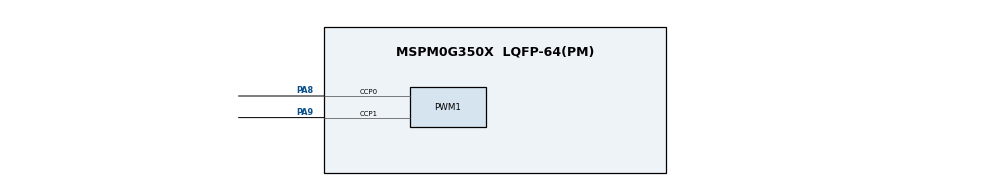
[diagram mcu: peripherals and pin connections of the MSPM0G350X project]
/**
 * @cliArgs --device "MSPM0G350X" --part "Default" --package "LQFP-64(PM)" --product "mspm0_sdk@2.05.01.01"
 * @versions {"tool":"1.24.0+4110"}
 */

/**
 * Import the modules used in this configuration.
 */
const ADC12         = scripting.addModule("/ti/driverlib/ADC12", {}, false);
const ADC121        = ADC12.addInstance();
const Board         = scripting.addModule("/ti/driverlib/Board");
const MATHACL       = scripting.addModule("/ti/driverlib/MATHACL");
const PWM           = scripting.addModule("/ti/driverlib/PWM", {}, false);
const PWM1          = PWM.addInstance();
const SYSCTL        = scripting.addModule("/ti/driverlib/SYSCTL");
const ProjectConfig = scripting.addModule("/ti/project_config/ProjectConfig");

/**
 * Write custom configuration values to the imported modules.
 */
const divider9       = system.clockTree["UDIV"];
divider9.divideValue = 2;

const multiplier2         = system.clockTree["PLL_QDIV"];
multiplier2.multiplyValue = 6;

const mux4       = system.clockTree["EXHFMUX"];
mux4.inputSelect = "EXHFMUX_XTAL";

const mux8       = system.clockTree["HSCLKMUX"];
mux8.inputSelect = "HSCLKMUX_SYSPLL0";

const mux12       = system.clockTree["SYSPLLMUX"];
mux12.inputSelect = "zSYSPLLMUX_HFCLK";

const pinFunction4        = system.clockTree["HFXT"];
pinFunction4.enable       = true;
pinFunction4.HFXTStartup  = 16;
pinFunction4.inputFreq    = 20;
pinFunction4.HFCLKMonitor = true;

ADC121.$name              = "ADC12_0";
ADC121.adcMem0chansel     = "DL_ADC12_INPUT_CHAN_11";
ADC121.repeatMode         = true;
ADC121.sampleTime0        = "50 us";
ADC121.enabledInterrupts  = ["DL_ADC12_INTERRUPT_MEM0_RESULT_LOADED"];
ADC121.adcMem0trig        = "DL_ADC12_TRIGGER_MODE_TRIGGER_NEXT";
ADC121.sampClkSrc         = "DL_ADC12_CLOCK_ULPCLK";
ADC121.sampClkDiv         = "DL_ADC12_CLOCK_DIVIDE_4";
ADC121.peripheral.$assign = "ADC0";


PWM1.$name                      = "PWM_0";
PWM1.timerStartTimer            = true;
PWM1.clockDivider               = 8;
PWM1.timerCount                 = 10000;
PWM1.peripheral.$assign         = "TIMA0";
PWM1.peripheral.ccp0Pin.$assign = "PA8";
PWM1.peripheral.ccp1Pin.$assign = "PA9";
PWM1.PWM_CHANNEL_0.$name        = "ti_driverlib_pwm_PWMTimerCC0";
PWM1.PWM_CHANNEL_0.dutyCycle    = 50;
PWM1.PWM_CHANNEL_1.$name        = "ti_driverlib_pwm_PWMTimerCC1";
PWM1.ccp0PinConfig.$name        = "ti_driverlib_gpio_GPIOPinGeneric0";
PWM1.ccp1PinConfig.$name        = "ti_driverlib_gpio_GPIOPinGeneric1";

SYSCTL.forceDefaultClkConfig = true;
SYSCTL.clockTreeEn           = true;

ProjectConfig.genLibIQ        = true;
ProjectConfig.genLibIQVersion = "MATHACL";

/**
 * Pinmux solution for unlocked pins/peripherals. This ensures that minor changes to the automatic solver in a future
 * version of the tool will not impact the pinmux you originally saw.  These lines can be completely deleted in order to
 * re-solve from scratch.
 */
pinFunction4.peripheral.$suggestSolution           = "SYSCTL";
pinFunction4.peripheral.hfxInPin.$suggestSolution  = "PA5";
pinFunction4.peripheral.hfxOutPin.$suggestSolution = "PA6";
Board.peripheral.$suggestSolution                  = "DEBUGSS";
Board.peripheral.swclkPin.$suggestSolution         = "PA20";
Board.peripheral.swdioPin.$suggestSolution         = "PA19";
